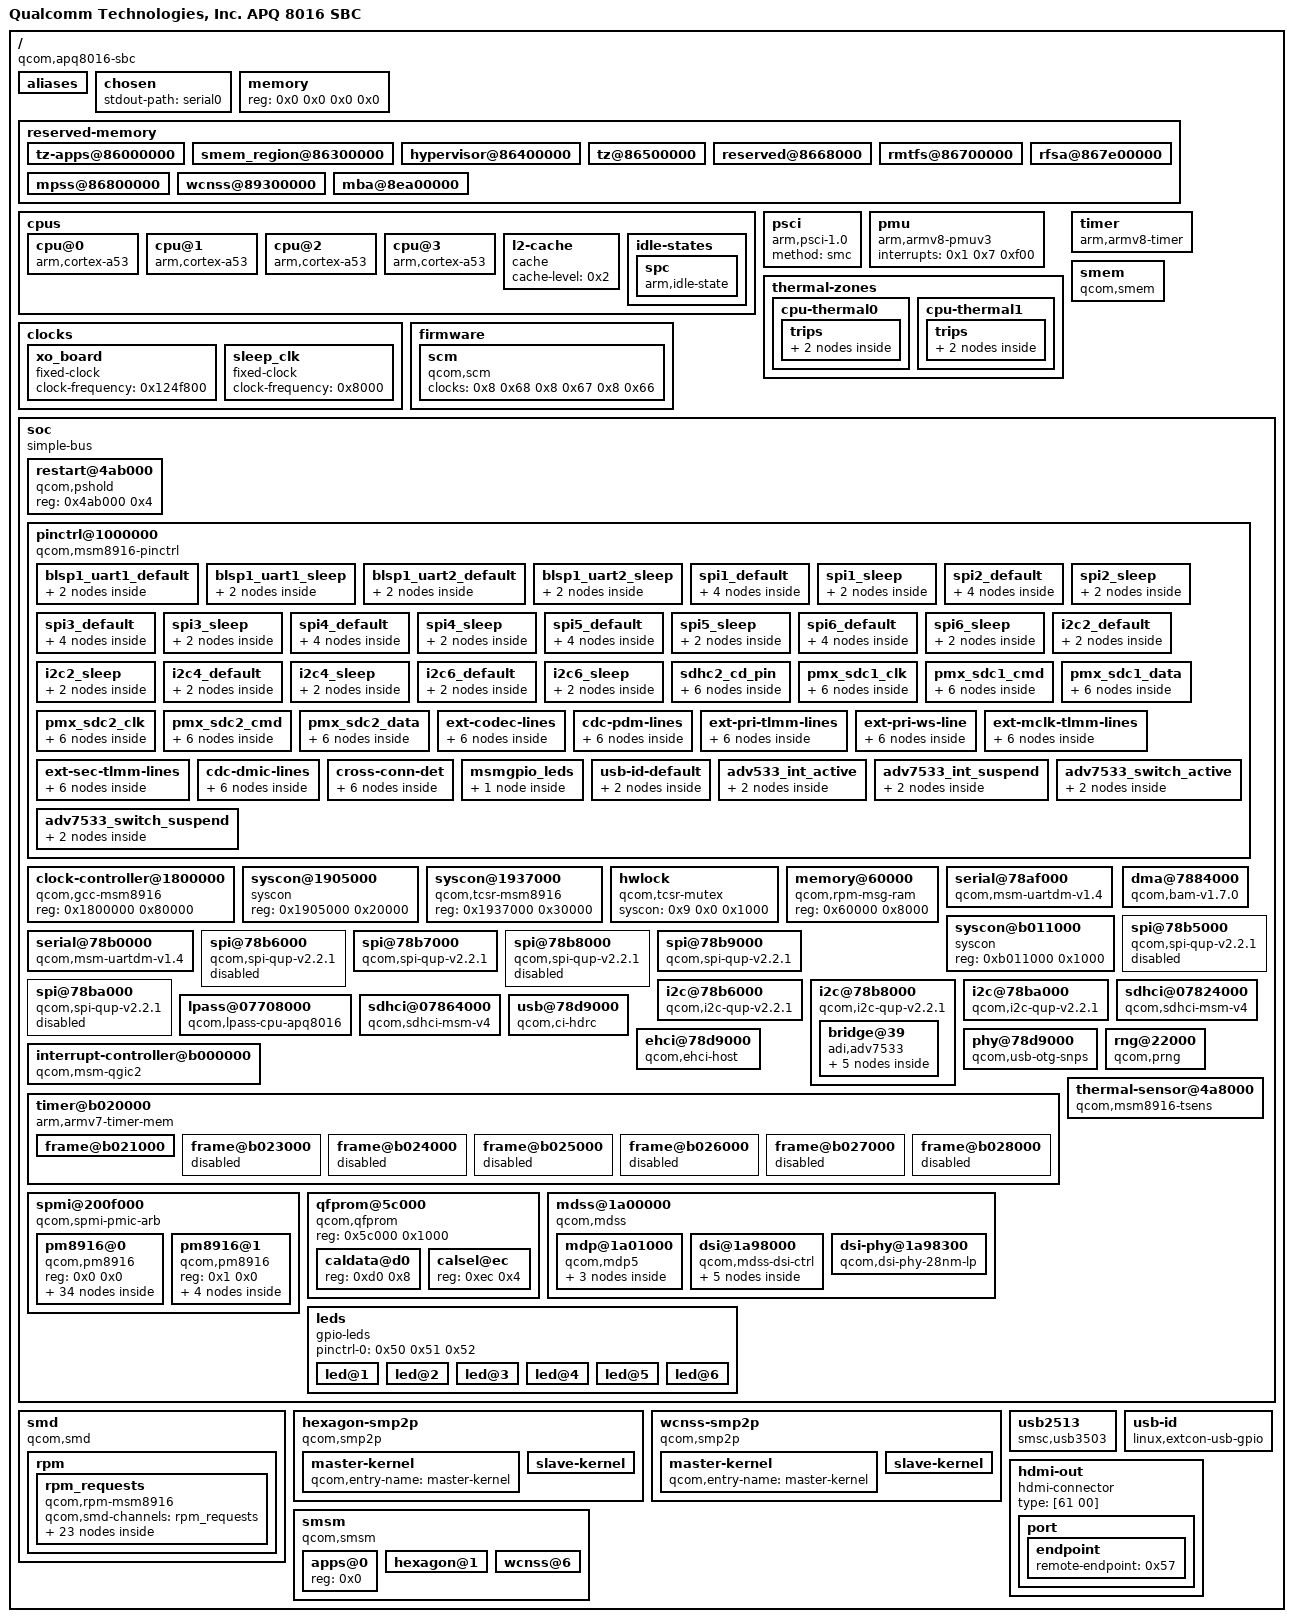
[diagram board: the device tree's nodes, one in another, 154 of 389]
/dts-v1/;

/ {
	model = "Qualcomm Technologies, Inc. APQ 8016 SBC";
	compatible = "qcom,apq8016-sbc", "qcom,apq8016", "qcom,sbc";
	interrupt-parent = <0x1>;
	#address-cells = <0x2>;
	#size-cells = <0x2>;

	aliases {
		sdhc1 = "/soc/sdhci@07824000";
		sdhc2 = "/soc/sdhci@07864000";
		serial0 = "/soc/serial@78b0000";
		serial1 = "/soc/serial@78af000";
		usid0 = "/soc/spmi@200f000/pm8916@0";
		i2c0 = "/soc/i2c@78b6000";
		i2c1 = "/soc/i2c@78ba000";
		i2c3 = "/soc/i2c@78b8000";
		spi0 = "/soc/spi@78b9000";
		spi1 = "/soc/spi@78b7000";
	};

	chosen {
		stdout-path = "serial0";
	};

	memory {
		device_type = "memory";
		reg = <0x0 0x0 0x0 0x0>;
	};

	reserved-memory {
		#address-cells = <0x2>;
		#size-cells = <0x2>;
		ranges;

		tz-apps@86000000 {
			reg = <0x0 0x86000000 0x0 0x300000>;
			no-map;
		};

		smem_region@86300000 {
			reg = <0x0 0x86300000 0x0 0x100000>;
			no-map;
			linux,phandle = <0x5>;
			phandle = <0x5>;
		};

		hypervisor@86400000 {
			reg = <0x0 0x86400000 0x0 0x100000>;
			no-map;
		};

		tz@86500000 {
			reg = <0x0 0x86500000 0x0 0x180000>;
			no-map;
		};

		reserved@8668000 {
			reg = <0x0 0x86680000 0x0 0x80000>;
			no-map;
		};

		rmtfs@86700000 {
			reg = <0x0 0x86700000 0x0 0xe0000>;
			no-map;
		};

		rfsa@867e00000 {
			reg = <0x0 0x867e0000 0x0 0x20000>;
			no-map;
		};

		mpss@86800000 {
			reg = <0x0 0x86800000 0x0 0x2b00000>;
			no-map;
		};

		wcnss@89300000 {
			reg = <0x0 0x89300000 0x0 0x600000>;
			no-map;
		};

		mba@8ea00000 {
			no-map;
			reg = <0x0 0x8ea00000 0x0 0x100000>;
		};
	};

	cpus {
		#address-cells = <0x1>;
		#size-cells = <0x0>;

		cpu@0 {
			device_type = "cpu";
			compatible = "arm,cortex-a53", "arm,armv8";
			reg = <0x0>;
			next-level-cache = <0x2>;
			enable-method = "psci";
			cpu-idle-states = <0x3>;
		};

		cpu@1 {
			device_type = "cpu";
			compatible = "arm,cortex-a53", "arm,armv8";
			reg = <0x1>;
			next-level-cache = <0x2>;
			enable-method = "psci";
			cpu-idle-states = <0x3>;
		};

		cpu@2 {
			device_type = "cpu";
			compatible = "arm,cortex-a53", "arm,armv8";
			reg = <0x2>;
			next-level-cache = <0x2>;
			enable-method = "psci";
			cpu-idle-states = <0x3>;
		};

		cpu@3 {
			device_type = "cpu";
			compatible = "arm,cortex-a53", "arm,armv8";
			reg = <0x3>;
			next-level-cache = <0x2>;
			enable-method = "psci";
			cpu-idle-states = <0x3>;
		};

		l2-cache {
			compatible = "cache";
			cache-level = <0x2>;
			linux,phandle = <0x2>;
			phandle = <0x2>;
		};

		idle-states {

			spc {
				compatible = "arm,idle-state";
				arm,psci-suspend-param = <0x40000002>;
				entry-latency-us = <0x82>;
				exit-latency-us = <0x96>;
				min-residency-us = <0x7d0>;
				local-timer-stop;
				linux,phandle = <0x3>;
				phandle = <0x3>;
			};
		};
	};

	psci {
		compatible = "arm,psci-1.0";
		method = "smc";
	};

	pmu {
		compatible = "arm,armv8-pmuv3";
		interrupts = <0x1 0x7 0xf00>;
	};

	thermal-zones {

		cpu-thermal0 {
			polling-delay-passive = <0xfa>;
			polling-delay = <0x3e8>;
			thermal-sensors = <0x4 0x4>;

			trips {

				trip0 {
					temperature = <0x124f8>;
					hysteresis = <0x7d0>;
					type = "passive";
				};

				trip1 {
					temperature = <0x1adb0>;
					hysteresis = <0x7d0>;
					type = "critical";
				};
			};
		};

		cpu-thermal1 {
			polling-delay-passive = <0xfa>;
			polling-delay = <0x3e8>;
			thermal-sensors = <0x4 0x3>;

			trips {

				trip0 {
					temperature = <0x124f8>;
					hysteresis = <0x7d0>;
					type = "passive";
				};

				trip1 {
					temperature = <0x1adb0>;
					hysteresis = <0x7d0>;
					type = "critical";
				};
			};
		};
	};

	timer {
		compatible = "arm,armv8-timer";
		interrupts = <0x1 0x2 0xf08 0x1 0x3 0xf08 0x1 0x4 0xf08 0x1 0x1 0xf08>;
	};

	clocks {

		xo_board {
			compatible = "fixed-clock";
			#clock-cells = <0x0>;
			clock-frequency = <0x124f800>;
		};

		sleep_clk {
			compatible = "fixed-clock";
			#clock-cells = <0x0>;
			clock-frequency = <0x8000>;
		};
	};

	smem {
		compatible = "qcom,smem";
		memory-region = <0x5>;
		qcom,rpm-msg-ram = <0x6>;
		hwlocks = <0x7 0x3>;
	};

	firmware {

		scm {
			compatible = "qcom,scm";
			clocks = <0x8 0x68 0x8 0x67 0x8 0x66>;
			clock-names = "core", "bus", "iface";
			#reset-cells = <0x1>;
		};
	};

	soc {
		#address-cells = <0x1>;
		#size-cells = <0x1>;
		ranges = <0x0 0x0 0x0 0xffffffff>;
		compatible = "simple-bus";

		restart@4ab000 {
			compatible = "qcom,pshold";
			reg = <0x4ab000 0x4>;
		};

		pinctrl@1000000 {
			compatible = "qcom,msm8916-pinctrl";
			reg = <0x1000000 0x300000>;
			interrupts = <0x0 0xd0 0x4>;
			gpio-controller;
			#gpio-cells = <0x2>;
			interrupt-controller;
			#interrupt-cells = <0x2>;
			linux,phandle = <0x1f>;
			phandle = <0x1f>;

			blsp1_uart1_default {
				linux,phandle = <0xb>;
				phandle = <0xb>;

				pinmux {
					function = "blsp_uart1";
					pins = "gpio0", "gpio1", "gpio2", "gpio3";
				};

				pinconf {
					pins = "gpio0", "gpio1", "gpio2", "gpio3";
					drive-strength = <0x10>;
					bias-disable;
				};
			};

			blsp1_uart1_sleep {
				linux,phandle = <0xc>;
				phandle = <0xc>;

				pinmux {
					function = "gpio";
					pins = "gpio0", "gpio1", "gpio2", "gpio3";
				};

				pinconf {
					pins = "gpio0", "gpio1", "gpio2", "gpio3";
					drive-strength = <0x2>;
					bias-pull-down;
				};
			};

			blsp1_uart2_default {
				linux,phandle = <0xd>;
				phandle = <0xd>;

				pinmux {
					function = "blsp_uart2";
					pins = "gpio4", "gpio5";
				};

				pinconf {
					pins = "gpio4", "gpio5";
					drive-strength = <0x10>;
					bias-disable;
				};
			};

			blsp1_uart2_sleep {
				linux,phandle = <0xe>;
				phandle = <0xe>;

				pinmux {
					function = "gpio";
					pins = "gpio4", "gpio5";
				};

				pinconf {
					pins = "gpio4", "gpio5";
					drive-strength = <0x2>;
					bias-pull-down;
				};
			};

			spi1_default {
				linux,phandle = <0xf>;
				phandle = <0xf>;

				pinmux {
					function = "blsp_spi1";
					pins = "gpio0", "gpio1", "gpio3";
				};

				pinmux_cs {
					function = "gpio";
					pins = "gpio2";
				};

				pinconf {
					pins = "gpio0", "gpio1", "gpio3";
					drive-strength = <0xc>;
					bias-disable;
				};

				pinconf_cs {
					pins = "gpio2";
					drive-strength = <0x10>;
					bias-disable;
					output-high;
				};
			};

			spi1_sleep {
				linux,phandle = <0x10>;
				phandle = <0x10>;

				pinmux {
					function = "gpio";
					pins = "gpio0", "gpio1", "gpio2", "gpio3";
				};

				pinconf {
					pins = "gpio0", "gpio1", "gpio2", "gpio3";
					drive-strength = <0x2>;
					bias-pull-down;
				};
			};

			spi2_default {
				linux,phandle = <0x11>;
				phandle = <0x11>;

				pinmux {
					function = "blsp_spi2";
					pins = "gpio4", "gpio5", "gpio7";
				};

				pinmux_cs {
					function = "gpio";
					pins = "gpio6";
				};

				pinconf {
					pins = "gpio4", "gpio5", "gpio7";
					drive-strength = <0xc>;
					bias-disable;
				};

				pinconf_cs {
					pins = "gpio6";
					drive-strength = <0x10>;
					bias-disable;
					output-high;
				};
			};

			spi2_sleep {
				linux,phandle = <0x12>;
				phandle = <0x12>;

				pinmux {
					function = "gpio";
					pins = "gpio4", "gpio5", "gpio6", "gpio7";
				};

				pinconf {
					pins = "gpio4", "gpio5", "gpio6", "gpio7";
					drive-strength = <0x2>;
					bias-pull-down;
				};
			};

			spi3_default {
				linux,phandle = <0x13>;
				phandle = <0x13>;

				pinmux {
					function = "blsp_spi3";
					pins = "gpio8", "gpio9", "gpio11";
				};

				pinmux_cs {
					function = "gpio";
					pins = "gpio10";
				};

				pinconf {
					pins = "gpio8", "gpio9", "gpio11";
					drive-strength = <0xc>;
					bias-disable;
				};

				pinconf_cs {
					pins = "gpio10";
					drive-strength = <0x10>;
					bias-disable;
					output-high;
				};
			};

			spi3_sleep {
				linux,phandle = <0x14>;
				phandle = <0x14>;

				pinmux {
					function = "gpio";
					pins = "gpio8", "gpio9", "gpio10", "gpio11";
				};

				pinconf {
					pins = "gpio8", "gpio9", "gpio10", "gpio11";
					drive-strength = <0x2>;
					bias-pull-down;
				};
			};

			spi4_default {
				linux,phandle = <0x15>;
				phandle = <0x15>;

				pinmux {
					function = "blsp_spi4";
					pins = "gpio12", "gpio13", "gpio15";
				};

				pinmux_cs {
					function = "gpio";
					pins = "gpio14";
				};

				pinconf {
					pins = "gpio12", "gpio13", "gpio15";
					drive-strength = <0xc>;
					bias-disable;
				};

				pinconf_cs {
					pins = "gpio14";
					drive-strength = <0x10>;
					bias-disable;
					output-high;
				};
			};

			spi4_sleep {
				linux,phandle = <0x16>;
				phandle = <0x16>;

				pinmux {
					function = "gpio";
					pins = "gpio12", "gpio13", "gpio14", "gpio15";
				};

				pinconf {
					pins = "gpio12", "gpio13", "gpio14", "gpio15";
					drive-strength = <0x2>;
					bias-pull-down;
				};
			};

			spi5_default {
				linux,phandle = <0x17>;
				phandle = <0x17>;

				pinmux {
					function = "blsp_spi5";
					pins = "gpio16", "gpio17", "gpio19";
				};

				pinmux_cs {
					function = "gpio";
					pins = "gpio18";
				};

				pinconf {
					pins = "gpio16", "gpio17", "gpio19";
					drive-strength = <0xc>;
					bias-disable;
				};

				pinconf_cs {
					pins = "gpio18";
					drive-strength = <0x10>;
					bias-disable;
					output-high;
				};
			};

			spi5_sleep {
				linux,phandle = <0x18>;
				phandle = <0x18>;

				pinmux {
					function = "gpio";
					pins = "gpio16", "gpio17", "gpio18", "gpio19";
				};

				pinconf {
					pins = "gpio16", "gpio17", "gpio18", "gpio19";
					drive-strength = <0x2>;
					bias-pull-down;
				};
			};

			spi6_default {
				linux,phandle = <0x19>;
				phandle = <0x19>;

				pinmux {
					function = "blsp_spi6";
					pins = "gpio20", "gpio21", "gpio23";
				};

				pinmux_cs {
					function = "gpio";
					pins = "gpio22";
				};

				pinconf {
					pins = "gpio20", "gpio21", "gpio23";
					drive-strength = <0xc>;
					bias-disable;
				};

				pinconf_cs {
					pins = "gpio22";
					drive-strength = <0x10>;
					bias-disable;
					output-high;
				};
			};

			spi6_sleep {
				linux,phandle = <0x1a>;
				phandle = <0x1a>;

				pinmux {
					function = "gpio";
					pins = "gpio20", "gpio21", "gpio22", "gpio23";
				};

				pinconf {
					pins = "gpio20", "gpio21", "gpio22", "gpio23";
					drive-strength = <0x2>;
					bias-pull-down;
				};
			};

			i2c2_default {
				linux,phandle = <0x1b>;
				phandle = <0x1b>;

				pinmux {
					function = "blsp_i2c2";
					pins = "gpio6", "gpio7";
				};

				pinconf {
					pins = "gpio6", "gpio7";
					drive-strength = <0x10>;
					bias-disable = <0x0>;
				};
			};

			i2c2_sleep {
				linux,phandle = <0x1c>;
				phandle = <0x1c>;

				pinmux {
					function = "gpio";
					pins = "gpio6", "gpio7";
				};

				pinconf {
					pins = "gpio6", "gpio7";
					drive-strength = <0x2>;
					bias-disable = <0x0>;
				};
			};

			i2c4_default {
				linux,phandle = <0x1d>;
				phandle = <0x1d>;

				pinmux {
					function = "blsp_i2c4";
					pins = "gpio14", "gpio15";
				};

				pinconf {
					pins = "gpio14", "gpio15";
					drive-strength = <0x10>;
					bias-disable = <0x0>;
				};
			};

			i2c4_sleep {
				linux,phandle = <0x1e>;
				phandle = <0x1e>;

				pinmux {
					function = "gpio";
					pins = "gpio14", "gpio15";
				};

				pinconf {
					pins = "gpio14", "gpio15";
					drive-strength = <0x2>;
					bias-disable = <0x0>;
				};
			};

			i2c6_default {
				linux,phandle = <0x28>;
				phandle = <0x28>;

				pinmux {
					function = "blsp_i2c6";
					pins = "gpio22", "gpio23";
				};

				pinconf {
					pins = "gpio22", "gpio23";
					drive-strength = <0x10>;
					bias-disable = <0x0>;
				};
			};

			i2c6_sleep {
				linux,phandle = <0x29>;
				phandle = <0x29>;

				pinmux {
					function = "gpio";
					pins = "gpio22", "gpio23";
				};

				pinconf {
					pins = "gpio22", "gpio23";
					drive-strength = <0x2>;
					bias-disable = <0x0>;
				};
			};

			sdhc2_cd_pin {

				cd_on {
					linux,phandle = <0x37>;
					phandle = <0x37>;

					pinmux {
						function = "gpio";
						pins = "gpio38";
					};

					pinconf {
						pins = "gpio38";
						drive-strength = <0x2>;
						bias-pull-up;
					};
				};

				cd_off {
					linux,phandle = <0x3b>;
					phandle = <0x3b>;

					pinmux {
						function = "gpio";
						pins = "gpio38";
					};

					pinconf {
						pins = "gpio38";
						drive-strength = <0x2>;
						bias-disable;
					};
				};
			};

			pmx_sdc1_clk {

				clk_on {
					linux,phandle = <0x2c>;
					phandle = <0x2c>;

					pinmux {
						pins = "sdc1_clk";
					};

					pinconf {
						pins = "sdc1_clk";
						bias-disable;
						drive-strength = <0x10>;
					};
				};

				clk_off {
					linux,phandle = <0x2f>;
					phandle = <0x2f>;

					pinmux {
						pins = "sdc1_clk";
					};

					pinconf {
						pins = "sdc1_clk";
						bias-disable;
						drive-strength = <0x2>;
					};
				};
			};

			pmx_sdc1_cmd {

				cmd_on {
					linux,phandle = <0x2d>;
					phandle = <0x2d>;

					pinmux {
						pins = "sdc1_cmd";
					};

					pinconf {
						pins = "sdc1_cmd";
						bias-pull-up;
						drive-strength = <0xa>;
					};
				};

				cmd_off {
					linux,phandle = <0x30>;
					phandle = <0x30>;

					pinmux {
						pins = "sdc1_cmd";
					};

					pinconf {
						pins = "sdc1_cmd";
						bias-pull-up;
						drive-strength = <0x2>;
					};
				};
			};

			pmx_sdc1_data {

				data_on {
					linux,phandle = <0x2e>;
					phandle = <0x2e>;

					pinmux {
						pins = "sdc1_data";
					};

					pinconf {
						pins = "sdc1_data";
						bias-pull-up;
						drive-strength = <0xa>;
					};
				};

				data_off {
					linux,phandle = <0x31>;
					phandle = <0x31>;

					pinmux {
						pins = "sdc1_data";
					};

					pinconf {
						pins = "sdc1_data";
						bias-pull-up;
						drive-strength = <0x2>;
					};
				};
			};

			pmx_sdc2_clk {

				clk_on {
					linux,phandle = <0x34>;
					phandle = <0x34>;

					pinmux {
						pins = "sdc2_clk";
					};

					pinconf {
						pins = "sdc2_clk";
						bias-disable;
						drive-strength = <0x10>;
					};
				};

				clk_off {
					linux,phandle = <0x38>;
					phandle = <0x38>;

					pinmux {
						pins = "sdc2_clk";
					};

					pinconf {
						pins = "sdc2_clk";
						bias-disable;
						drive-strength = <0x2>;
					};
				};
			};

			pmx_sdc2_cmd {

				cmd_on {
					linux,phandle = <0x35>;
					phandle = <0x35>;

					pinmux {
						pins = "sdc2_cmd";
					};

					pinconf {
						pins = "sdc2_cmd";
						bias-pull-up;
						drive-strength = <0xa>;
					};
				};

				cmd_off {
					linux,phandle = <0x39>;
					phandle = <0x39>;

					pinmux {
						pins = "sdc2_cmd";
					};

					pinconf {
						pins = "sdc2_cmd";
						bias-pull-up;
						drive-strength = <0x2>;
					};
				};
			};

			pmx_sdc2_data {

				data_on {
					linux,phandle = <0x36>;
					phandle = <0x36>;

					pinmux {
						pins = "sdc2_data";
					};

					pinconf {
						pins = "sdc2_data";
						bias-pull-up;
						drive-strength = <0xa>;
					};
				};

				data_off {
					linux,phandle = <0x3a>;
					phandle = <0x3a>;

					pinmux {
						pins = "sdc2_data";
					};

					pinconf {
						pins = "sdc2_data";
						bias-pull-up;
						drive-strength = <0x2>;
					};
				};
			};

			ext-codec-lines {

				lines_on {

					pinmux {
						function = "gpio";
						pins = "gpio67";
					};

					pinconf {
						pins = "gpio67";
						drive-strength = <0x8>;
						bias-disable;
						output-high;
					};
				};

				lines_off {

					pinmux {
						function = "gpio";
						pins = "gpio67";
					};

					pinconf {
						pins = "gpio67";
						drive-strength = <0x2>;
						bias-disable;
					};
				};
			};

			cdc-pdm-lines {

				pdm_lines_on {

					pinmux {
						function = "cdc_pdm0";
						pins = "gpio63", "gpio64", "gpio65", "gpio66", "gpio67", "gpio68";
					};

					pinconf {
						pins = "gpio63", "gpio64", "gpio65", "gpio66", "gpio67", "gpio68";
						drive-strength = <0x8>;
						bias-disable;
					};
				};

				pdm_lines_off {

					pinmux {
						function = "cdc_pdm0";
						pins = "gpio63", "gpio64", "gpio65", "gpio66", "gpio67", "gpio68";
					};

					pinconf {
						pins = "gpio63", "gpio64", "gpio65", "gpio66", "gpio67", "gpio68";
						drive-strength = <0x2>;
						bias-pull-down;
					};
				};
			};

			ext-pri-tlmm-lines {

				ext_pa_on {

					pinmux {
						function = "pri_mi2s";
						pins = "gpio113", "gpio114", "gpio115", "gpio116";
					};

					pinconf {
						pins = "gpio113", "gpio114", "gpio115", "gpio116";
						drive-strength = <0x8>;
						bias-disable;
					};
				};

				ext_pa_off {

					pinmux {
						function = "pri_mi2s";
						pins = "gpio113", "gpio114", "gpio115", "gpio116";
					};

					pinconf {
						pins = "gpio113", "gpio114", "gpio115", "gpio116";
						drive-strength = <0x2>;
						bias-disable;
					};
				};
			};

			ext-pri-ws-line {

				ext_pa_on {

					pinmux {
						function = "pri_mi2s_ws";
						pins = "gpio110";
					};

					pinconf {
						pins = "gpio110";
						drive-strength = <0x8>;
						bias-disable;
					};
				};

				ext_pa_off {

					pinmux {
						function = "pri_mi2s_ws";
						pins = "gpio110";
					};

					pinconf {
						pins = "gpio110";
						drive-strength = <0x2>;
						bias-disable;
					};
				};
			};

			ext-mclk-tlmm-lines {

				mclk_lines_on {

					pinmux {
						function = "pri_mi2s";
						pins = "gpio116";
					};

					pinconf {
						pins = "gpio116";
						drive-strength = <0x8>;
						bias-disable;
					};
				};

				mclk_lines_off {

					pinmux {
						function = "pri_mi2s";
						pins = "gpio116";
					};

					pinconf {
						pins = "gpio116";
						drive-strength = <0x2>;
						bias-disable;
					};
				};
			};

			ext-sec-tlmm-lines {

				tlmm_lines_on {

					pinmux {
						function = "sec_mi2s";
						pins = "gpio112", "gpio117", "gpio118", "gpio119";
					};

					pinconf {
						pins = "gpio112", "gpio117", "gpio118", "gpio119";
						drive-strength = <0x8>;
						bias-disable;
					};
				};

				tlmm_lines_off {

					pinmux {
						function = "sec_mi2s";
						pins = "gpio112", "gpio117", "gpio118", "gpio119";
					};

					pinconf {
						pins = "gpio112", "gpio117", "gpio118", "gpio119";
						drive-strength = <0x2>;
						bias-disable;
					};
				};
			};

			cdc-dmic-lines {

				dmic_lines_on {

					pinmux_dmic0_clk {
						function = "dmic0_clk";
						pins = "gpio0";
					};

					pinmux_dmic0_data {
						function = "dmic0_data";
						pins = "gpio1";
					};

					pinconf {
						pins = "gpio0", "gpio1";
						drive-strength = <0x8>;
					};
				};

				dmic_lines_off {

					pinconf {
						pins = "gpio0", "gpio1";
						drive-strength = <0x2>;
						bias-disable;
					};
				};
			};

			cross-conn-det {

				lines_on {

					pinmux {
						function = "gpio";
						pins = "gpio120";
					};

					pinconf {
						pins = "gpio120";
						drive-strength = <0x8>;
						output-low;
						bias-pull-down;
					};
				};

				lines_off {

					pinmux {
						function = "gpio";
						pins = "gpio120";
					};

					pinconf {
						pins = "gpio120";
						drive-strength = <0x2>;
						bias-disable;
					};
				};
			};

			msmgpio_leds {
				linux,phandle = <0x50>;
				phandle = <0x50>;

				pinconf {
					pins = "gpio21", "gpio120";
					function = "gpio";
					output-low;
				};
			};

			usb-id-default {
				linux,phandle = <0x56>;
				phandle = <0x56>;

				pinmux {
					function = "gpio";
					pins = "gpio121";
				};

				pinconf {
					pins = "gpio121";
					drive-strength = <0x8>;
					input-enable;
					bias-pull-up;
				};
			};

			adv533_int_active {
				linux,phandle = <0x22>;
				phandle = <0x22>;

				pinmux {
					function = "gpio";
					pins = "gpio31";
				};

				pinconf {
					pins = "gpio31";
					drive-strength = <0x10>;
					bias-disable;
				};
			};

			adv7533_int_suspend {
				linux,phandle = <0x24>;
				phandle = <0x24>;

				pinmux {
					function = "gpio";
					pins = "gpio31";
				};

				pinconf {
					pins = "gpio31";
					drive-strength = <0x2>;
					bias-disable;
				};
			};

			adv7533_switch_active {
				linux,phandle = <0x23>;
				phandle = <0x23>;

				pinmux {
					function = "gpio";
					pins = "gpio32";
				};

				pinconf {
					pins = "gpio32";
					drive-strength = <0x10>;
					bias-disable;
				};
			};

			adv7533_switch_suspend {
				linux,phandle = <0x25>;
				phandle = <0x25>;

				pinmux {
					function = "gpio";
					pins = "gpio32";
				};

				pinconf {
					pins = "gpio32";
					drive-strength = <0x2>;
					bias-disable;
				};
			};
		};

		clock-controller@1800000 {
			compatible = "qcom,gcc-msm8916";
			#clock-cells = <0x1>;
			#reset-cells = <0x1>;
			#power-domain-cells = <0x1>;
			reg = <0x1800000 0x80000>;
			linux,phandle = <0x8>;
			phandle = <0x8>;
		};

		syscon@1905000 {
			compatible = "syscon";
			reg = <0x1905000 0x20000>;
			linux,phandle = <0x9>;
			phandle = <0x9>;
		};

		syscon@1937000 {
			compatible = "qcom,tcsr-msm8916", "syscon";
			reg = <0x1937000 0x30000>;
		};

		hwlock {
			compatible = "qcom,tcsr-mutex";
			syscon = <0x9 0x0 0x1000>;
			#hwlock-cells = <0x1>;
			linux,phandle = <0x7>;
			phandle = <0x7>;
		};

		memory@60000 {
			compatible = "qcom,rpm-msg-ram";
			reg = <0x60000 0x8000>;
			linux,phandle = <0x6>;
			phandle = <0x6>;
		};

		serial@78af000 {
			compatible = "qcom,msm-uartdm-v1.4", "qcom,msm-uartdm";
			reg = <0x78af000 0x200>;
			interrupts = <0x0 0x6b 0x4>;
			clocks = <0x8 0x44 0x8 0x36>;
			clock-names = "core", "iface";
			dmas = <0xa 0x1 0xa 0x0>;
			dma-names = "rx", "tx";
			status = "okay";
			label = "LS-UART0";
			pinctrl-names = "default", "sleep";
			pinctrl-0 = <0xb>;
			pinctrl-1 = <0xc>;
		};

		syscon@b011000 {
			compatible = "syscon";
			reg = <0xb011000 0x1000>;
			linux,phandle = <0x54>;
			phandle = <0x54>;
		};

		serial@78b0000 {
			compatible = "qcom,msm-uartdm-v1.4", "qcom,msm-uartdm";
			reg = <0x78b0000 0x200>;
			interrupts = <0x0 0x6c 0x4>;
			clocks = <0x8 0x45 0x8 0x36>;
			clock-names = "core", "iface";
			dmas = <0xa 0x3 0xa 0x2>;
			dma-names = "rx", "tx";
			status = "okay";
			label = "LS-UART1";
			pinctrl-names = "default", "sleep";
			pinctrl-0 = <0xd>;
			pinctrl-1 = <0xe>;
		};

		dma@7884000 {
			compatible = "qcom,bam-v1.7.0";
			reg = <0x7884000 0x23000>;
			interrupts = <0x0 0xee 0x4>;
			clocks = <0x8 0x36>;
			clock-names = "bam_clk";
			#dma-cells = <0x1>;
			qcom,ee = <0x0>;
			status = "okay";
			linux,phandle = <0xa>;
			phandle = <0xa>;
		};

		spi@78b5000 {
			compatible = "qcom,spi-qup-v2.2.1";
			reg = <0x78b5000 0x600>;
			interrupts = <0x0 0x5f 0x4>;
			clocks = <0x8 0x39 0x8 0x36>;
			clock-names = "core", "iface";
			dmas = <0xa 0x5 0xa 0x4>;
			dma-names = "rx", "tx";
			pinctrl-names = "default", "sleep";
			pinctrl-0 = <0xf>;
			pinctrl-1 = <0x10>;
			#address-cells = <0x1>;
			#size-cells = <0x0>;
			status = "disabled";
		};

		spi@78b6000 {
			compatible = "qcom,spi-qup-v2.2.1";
			reg = <0x78b6000 0x600>;
			interrupts = <0x0 0x60 0x4>;
			clocks = <0x8 0x3b 0x8 0x36>;
			clock-names = "core", "iface";
			dmas = <0xa 0x7 0xa 0x6>;
			dma-names = "rx", "tx";
			pinctrl-names = "default", "sleep";
			pinctrl-0 = <0x11>;
			pinctrl-1 = <0x12>;
			#address-cells = <0x1>;
			#size-cells = <0x0>;
			status = "disabled";
		};

		spi@78b7000 {
			compatible = "qcom,spi-qup-v2.2.1";
			reg = <0x78b7000 0x600>;
			interrupts = <0x0 0x61 0x4>;
			clocks = <0x8 0x3d 0x8 0x36>;
			clock-names = "core", "iface";
			dmas = <0xa 0x9 0xa 0x8>;
			dma-names = "rx", "tx";
			pinctrl-names = "default", "sleep";
			pinctrl-0 = <0x13>;
			pinctrl-1 = <0x14>;
			#address-cells = <0x1>;
			#size-cells = <0x0>;
			status = "okay";
			label = "HS-SPI1";
		};

		spi@78b8000 {
			compatible = "qcom,spi-qup-v2.2.1";
			reg = <0x78b8000 0x600>;
			interrupts = <0x0 0x62 0x4>;
			clocks = <0x8 0x3f 0x8 0x36>;
			clock-names = "core", "iface";
			dmas = <0xa 0xb 0xa 0xa>;
			dma-names = "rx", "tx";
			pinctrl-names = "default", "sleep";
			pinctrl-0 = <0x15>;
			pinctrl-1 = <0x16>;
			#address-cells = <0x1>;
			#size-cells = <0x0>;
			status = "disabled";
		};

		spi@78b9000 {
			compatible = "qcom,spi-qup-v2.2.1";
			reg = <0x78b9000 0x600>;
			interrupts = <0x0 0x63 0x4>;
			clocks = <0x8 0x41 0x8 0x36>;
			clock-names = "core", "iface";
			dmas = <0xa 0xd 0xa 0xc>;
			dma-names = "rx", "tx";
			pinctrl-names = "default", "sleep";
			pinctrl-0 = <0x17>;
			pinctrl-1 = <0x18>;
			#address-cells = <0x1>;
			#size-cells = <0x0>;
			status = "okay";
			label = "LS-SPI0";
		};

		spi@78ba000 {
			compatible = "qcom,spi-qup-v2.2.1";
			reg = <0x78ba000 0x600>;
			interrupts = <0x0 0x64 0x4>;
			clocks = <0x8 0x43 0x8 0x36>;
			clock-names = "core", "iface";
			dmas = <0xa 0xf 0xa 0xe>;
			dma-names = "rx", "tx";
			pinctrl-names = "default", "sleep";
			pinctrl-0 = <0x19>;
			pinctrl-1 = <0x1a>;
			#address-cells = <0x1>;
			#size-cells = <0x0>;
			status = "disabled";
		};

		i2c@78b6000 {
			compatible = "qcom,i2c-qup-v2.2.1";
			reg = <0x78b6000 0x1000>;
			interrupts = <0x0 0x60 0x0>;
			clocks = <0x8 0x36 0x8 0x3a>;
			clock-names = "iface", "core";
			pinctrl-names = "default", "sleep";
			pinctrl-0 = <0x1b>;
			pinctrl-1 = <0x1c>;
			#address-cells = <0x1>;
			#size-cells = <0x0>;
			status = "okay";
			label = "LS-I2C0";
		};

		i2c@78b8000 {
			compatible = "qcom,i2c-qup-v2.2.1";
			reg = <0x78b8000 0x1000>;
			interrupts = <0x0 0x62 0x0>;
			clocks = <0x8 0x36 0x8 0x3e>;
			clock-names = "iface", "core";
			pinctrl-names = "default", "sleep";
			pinctrl-0 = <0x1d>;
			pinctrl-1 = <0x1e>;
			#address-cells = <0x1>;
			#size-cells = <0x0>;
			status = "okay";
			label = "HS-I2C2";

			bridge@39 {
				status = "okay";
				compatible = "adi,adv7533";
				reg = <0x39>;
				interrupt-parent = <0x1f>;
				interrupts = <0x1f 0x2>;
				adi,dsi-lanes = <0x4>;
				pd-gpios = <0x1f 0x20 0x0>;
				avdd-supply = <0x20>;
				v1p2-supply = <0x20>;
				v3p3-supply = <0x21>;
				pinctrl-names = "default", "sleep";
				pinctrl-0 = <0x22 0x23>;
				pinctrl-1 = <0x24 0x25>;

				ports {
					#address-cells = <0x1>;
					#size-cells = <0x0>;

					port@0 {
						reg = <0x0>;

						endpoint {
							remote-endpoint = <0x26>;
							linux,phandle = <0x4f>;
							phandle = <0x4f>;
						};
					};

					port@1 {
						reg = <0x1>;

						endpoint {
							remote-endpoint = <0x27>;
							linux,phandle = <0x57>;
							phandle = <0x57>;
						};
					};
				};
			};
		};

		i2c@78ba000 {
			compatible = "qcom,i2c-qup-v2.2.1";
			reg = <0x78ba000 0x1000>;
			interrupts = <0x0 0x64 0x0>;
			clocks = <0x8 0x36 0x8 0x42>;
			clock-names = "iface", "core";
			pinctrl-names = "default", "sleep";
			pinctrl-0 = <0x28>;
			pinctrl-1 = <0x29>;
			#address-cells = <0x1>;
			#size-cells = <0x0>;
			status = "okay";
			label = "LS-I2C1";
		};

		lpass@07708000 {
			status = "okay";
			compatible = "qcom,lpass-cpu-apq8016";
			clocks = <0x8 0x9a 0x8 0x96 0x8 0x97 0x8 0x9c 0x8 0x9d 0x8 0x9d 0x8 0x9e>;
			clock-names = "ahbix-clk", "pcnoc-mport-clk", "pcnoc-sway-clk", "mi2s-bit-clk0", "mi2s-bit-clk1", "mi2s-bit-clk2", "mi2s-bit-clk3";
			#sound-dai-cells = <0x1>;
			interrupts = <0x0 0xa0 0x0>;
			interrupt-names = "lpass-irq-lpaif";
			reg = <0x7708000 0x10000>;
			reg-names = "lpass-lpaif";
		};

		sdhci@07824000 {
			compatible = "qcom,sdhci-msm-v4";
			reg = <0x7824900 0x11c 0x7824000 0x800>;
			reg-names = "hc_mem", "core_mem";
			interrupts = <0x0 0x7b 0x0 0x0 0x8a 0x0>;
			interrupt-names = "hc_irq", "pwr_irq";
			clocks = <0x8 0x7b 0x8 0x7a>;
			clock-names = "core", "iface";
			bus-width = <0x8>;
			non-removable;
			status = "okay";
			vmmc-supply = <0x2a>;
			vqmmc-supply = <0x2b>;
			pinctrl-names = "default", "sleep";
			pinctrl-0 = <0x2c 0x2d 0x2e>;
			pinctrl-1 = <0x2f 0x30 0x31>;
		};

		sdhci@07864000 {
			compatible = "qcom,sdhci-msm-v4";
			reg = <0x7864900 0x11c 0x7864000 0x800>;
			reg-names = "hc_mem", "core_mem";
			interrupts = <0x0 0x7d 0x0 0x0 0xdd 0x0>;
			interrupt-names = "hc_irq", "pwr_irq";
			clocks = <0x8 0x7d 0x8 0x7c>;
			clock-names = "core", "iface";
			bus-width = <0x4>;
			status = "okay";
			vmmc-supply = <0x32>;
			vqmmc-supply = <0x33>;
			pinctrl-names = "default", "sleep";
			pinctrl-0 = <0x34 0x35 0x36 0x37>;
			pinctrl-1 = <0x38 0x39 0x3a 0x3b>;
			cd-gpios = <0x1f 0x26 0x1>;
		};

		usb@78d9000 {
			compatible = "qcom,ci-hdrc";
			reg = <0x78d9000 0x400>;
			dr_mode = "peripheral";
			interrupts = <0x0 0x86 0x4>;
			usb-phy = <0x3c>;
			status = "okay";
			extcon = <0x3d 0x3d>;
		};

		ehci@78d9000 {
			compatible = "qcom,ehci-host";
			reg = <0x78d9000 0x400>;
			interrupts = <0x0 0x86 0x4>;
			usb-phy = <0x3c>;
			status = "okay";
		};

		phy@78d9000 {
			compatible = "qcom,usb-otg-snps";
			reg = <0x78d9000 0x400>;
			interrupts = <0x0 0x86 0x4 0x0 0x8c 0x4>;
			qcom,vdd-levels = <0x7a120 0xf4240 0x142440>;
			qcom,phy-init-sequence = <0x44 0x6b 0x24 0x13>;
			dr_mode = "otg";
			qcom,otg-control = <0x2>;
			qcom,manual-pullup;
			clocks = <0x8 0x85 0x8 0x86 0x8 0x84>;
			clock-names = "iface", "core", "sleep";
			resets = <0x8 0x23 0x8 0x22>;
			reset-names = "phy", "link";
			status = "okay";
			v1p8-supply = <0x3e>;
			v3p3-supply = <0x3f>;
			vddcx-supply = <0x40>;
			extcon = <0x3d 0x3d>;
			switch-gpio = <0x41 0x4 0x0>;
			pinctrl-names = "default";
			pinctrl-0 = <0x42>;
			linux,phandle = <0x3c>;
			phandle = <0x3c>;
		};

		interrupt-controller@b000000 {
			compatible = "qcom,msm-qgic2";
			interrupt-controller;
			#interrupt-cells = <0x3>;
			reg = <0xb000000 0x1000 0xb002000 0x1000>;
			linux,phandle = <0x1>;
			phandle = <0x1>;
		};

		timer@b020000 {
			#address-cells = <0x1>;
			#size-cells = <0x1>;
			ranges;
			compatible = "arm,armv7-timer-mem";
			reg = <0xb020000 0x1000>;
			clock-frequency = <0x124f800>;

			frame@b021000 {
				frame-number = <0x0>;
				interrupts = <0x0 0x8 0x4 0x0 0x7 0x4>;
				reg = <0xb021000 0x1000 0xb022000 0x1000>;
			};

			frame@b023000 {
				frame-number = <0x1>;
				interrupts = <0x0 0x9 0x4>;
				reg = <0xb023000 0x1000>;
				status = "disabled";
			};

			frame@b024000 {
				frame-number = <0x2>;
				interrupts = <0x0 0xa 0x4>;
				reg = <0xb024000 0x1000>;
				status = "disabled";
			};

			frame@b025000 {
				frame-number = <0x3>;
				interrupts = <0x0 0xb 0x4>;
				reg = <0xb025000 0x1000>;
				status = "disabled";
			};

			frame@b026000 {
				frame-number = <0x4>;
				interrupts = <0x0 0xc 0x4>;
				reg = <0xb026000 0x1000>;
				status = "disabled";
			};

			frame@b027000 {
				frame-number = <0x5>;
				interrupts = <0x0 0xd 0x4>;
				reg = <0xb027000 0x1000>;
				status = "disabled";
			};

			frame@b028000 {
				frame-number = <0x6>;
				interrupts = <0x0 0xe 0x4>;
				reg = <0xb028000 0x1000>;
				status = "disabled";
			};
		};

		spmi@200f000 {
			compatible = "qcom,spmi-pmic-arb";
			reg = <0x200f000 0x1000 0x2400000 0x400000 0x2c00000 0x400000 0x3800000 0x200000 0x200a000 0x2100>;
			reg-names = "core", "chnls", "obsrvr", "intr", "cnfg";
			interrupt-names = "periph_irq";
			interrupts = <0x0 0xbe 0x4>;
			qcom,ee = <0x0>;
			qcom,channel = <0x0>;
			#address-cells = <0x2>;
			#size-cells = <0x0>;
			interrupt-controller;
			#interrupt-cells = <0x4>;
			linux,phandle = <0x46>;
			phandle = <0x46>;

			pm8916@0 {
				compatible = "qcom,pm8916", "qcom,spmi-pmic";
				reg = <0x0 0x0>;
				#address-cells = <0x1>;
				#size-cells = <0x1>;

				qcom,revid@100 {
					compatible = "qcom,qpnp-revid";
					reg = <0x100 0x100>;
					linux,phandle = <0x43>;
					phandle = <0x43>;
				};

				qcom,power-on@800 {
					compatible = "qcom,qpnp-power-on";
					reg = <0x800 0x100>;
					interrupts = <0x0 0x8 0x0 0x0 0x0 0x8 0x1 0x0>;
					interrupt-names = "kpdpwr", "resin";
					qcom,pon-dbc-delay = <0x3d09>;
					qcom,system-reset;
					qcom,clear-warm-reset;
					qcom,store-hard-reset-reason;

					qcom,pon_1 {
						qcom,pon-type = <0x0>;
						qcom,support-reset = <0x1>;
						qcom,pull-up = <0x1>;
						qcom,s1-timer = <0x2810>;
						qcom,s2-timer = <0x7d0>;
						qcom,s2-type = <0x1>;
						linux,code = <0x74>;
					};

					qcom,pon_2 {
						qcom,pon-type = <0x1>;
						qcom,pull-up = <0x1>;
						linux,code = <0x72>;
					};
				};

				pinctrl@c000 {
					compatible = "qcom,pm8916-gpio";
					reg = <0xc000 0x400>;
					gpio-controller;
					#gpio-cells = <0x2>;
					interrupts = <0x0 0xc0 0x0 0x0 0x0 0xc1 0x0 0x0 0x0 0xc2 0x0 0x0 0x0 0xc3 0x0 0x0>;
					interrupt-names = "pm8916_gpio1", "pm8916_gpio2", "pm8916_gpio3", "pm8916_gpio4";
					linux,phandle = <0x41>;
					phandle = <0x41>;

					usb_hub_reset_pm {

						pinconf {
							pins = "gpio3";
							function = "normal";
							output-low;
						};
					};

					usb_sw_sel_pm {
						linux,phandle = <0x42>;
						phandle = <0x42>;

						pinconf {
							pins = "gpio4";
							function = "normal";
							power-source = <0x0>;
							input-disable;
						};
					};

					pm8916_gpios_leds {
						linux,phandle = <0x51>;
						phandle = <0x51>;

						pinconf {
							pins = "gpio1", "gpio2";
							function = "normal";
							output-low;
						};
					};
				};

				mpps@a000 {
					compatible = "qcom,pm8916-mpp";
					reg = <0xa000 0x400>;
					gpio-controller;
					#gpio-cells = <0x2>;
					interrupts = <0x0 0xa0 0x0 0x0 0x0 0xa1 0x0 0x0 0x0 0xa2 0x0 0x0 0x0 0xa3 0x0 0x0>;
					interrupt-names = "pm8916_mpp1", "pm8916_mpp2", "pm8916_mpp3", "pm8916_mpp4";
					linux,phandle = <0x53>;
					phandle = <0x53>;

					pm8916_mpps_leds {
						linux,phandle = <0x52>;
						phandle = <0x52>;

						pinconf {
							pins = "mpp2", "mpp3";
							function = "digital";
							output-low;
						};
					};
				};

				qcom,coincell@2800 {
					compatible = "qcom,qpnp-coincell";
					reg = <0x2800 0x100>;
				};

				qcom,pm8916_rtc {
					compatible = "qcom,qpnp-rtc";
					#address-cells = <0x1>;
					#size-cells = <0x1>;
					qcom,qpnp-rtc-write = <0x0>;
					qcom,qpnp-rtc-alarm-pwrup = <0x0>;

					qcom,pm8916_rtc_rw@6000 {
						reg = <0x6000 0x100>;
					};

					qcom,pm8916_rtc_alarm@6100 {
						reg = <0x6100 0x100>;
						interrupts = <0x0 0x61 0x1 0x0>;
					};
				};

				vadc@3100 {
					compatible = "qcom,qpnp-vadc";
					reg = <0x3100 0x100>;
					#address-cells = <0x1>;
					#size-cells = <0x0>;
					interrupts = <0x0 0x31 0x0 0x1>;
					interrupt-names = "eoc-int-en-set";
					qcom,adc-bit-resolution = <0xf>;
					qcom,adc-vdd-reference = <0x708>;
					qcom,vadc-poll-eoc;
					qcom,pmic-revid = <0x43>;
					#thermal-sensor-cells = <0x1>;
					linux,phandle = <0x44>;
					phandle = <0x44>;

					chan@8 {
						label = "die_temp";
						reg = <0x8>;
						qcom,decimation = <0x0>;
						qcom,pre-div-channel-scaling = <0x0>;
						qcom,calibration-type = "absolute";
						qcom,scale-function = <0x3>;
						qcom,hw-settle-time = <0x0>;
						qcom,fast-avg-setup = <0x0>;
					};

					chan@9 {
						label = "ref_625mv";
						reg = <0x9>;
						qcom,decimation = <0x0>;
						qcom,pre-div-channel-scaling = <0x0>;
						qcom,calibration-type = "absolute";
						qcom,scale-function = <0x0>;
						qcom,hw-settle-time = <0x0>;
						qcom,fast-avg-setup = <0x0>;
					};

					chan@a {
						label = "ref_1250v";
						reg = <0xa>;
						qcom,decimation = <0x0>;
						qcom,pre-div-channel-scaling = <0x0>;
						qcom,calibration-type = "absolute";
						qcom,scale-function = <0x0>;
						qcom,hw-settle-time = <0x0>;
						qcom,fast-avg-setup = <0x0>;
					};
				};

				qcom,temp-alarm@2400 {
					compatible = "qcom,qpnp-temp-alarm";
					reg = <0x2400 0x100>;
					interrupts = <0x0 0x24 0x0 0x1>;
					label = "pm8916_tz";
					qcom,channel-num = <0x8>;
					qcom,threshold-set = <0x0>;
					qcom,temp_alarm-vadc = <0x44>;
					#thermal-sensor-cells = <0x0>;
				};

				vadc@3400 {
					compatible = "qcom,qpnp-adc-tm";
					reg = <0x3400 0x100>;
					#address-cells = <0x1>;
					#size-cells = <0x0>;
					interrupts = <0x0 0x34 0x0 0x1 0x0 0x34 0x3 0x1 0x0 0x34 0x4 0x1>;
					interrupt-names = "eoc-int-en-set", "high-thr-en-set", "low-thr-en-set";
					qcom,adc-bit-resolution = <0xf>;
					qcom,adc-vdd-reference = <0x708>;
					qcom,adc_tm-vadc = <0x44>;
					qcom,pmic-revid = <0x43>;
					linux,phandle = <0x45>;
					phandle = <0x45>;
				};

				qcom,charger {
					compatible = "qcom,qpnp-linear-charger";
					#address-cells = <0x1>;
					#size-cells = <0x1>;
					#cooling-cells = <0x2>;
					qcom,vddmax-mv = <0x1068>;
					qcom,vddsafe-mv = <0x1068>;
					qcom,vinmin-mv = <0x10d4>;
					qcom,ibatsafe-ma = <0x5a0>;
					qcom,thermal-mitigation = <0x5a0 0x2d0 0x276 0x0>;
					qcom,cool-bat-decidegc = <0x64>;
					qcom,warm-bat-decidegc = <0x1c2>;
					qcom,cool-bat-mv = <0x1004>;
					qcom,warm-bat-mv = <0x1004>;
					qcom,ibatmax-warm-ma = <0x168>;
					qcom,ibatmax-cool-ma = <0x168>;
					qcom,batt-hot-percentage = <0x19>;
					qcom,batt-cold-percentage = <0x50>;
					qcom,tchg-mins = <0xe8>;
					qcom,resume-soc = <0x63>;
					qcom,chg-vadc = <0x44>;
					qcom,chg-adc_tm = <0x45>;
					status = "disabled";

					qcom,chgr@1000 {
						reg = <0x1000 0x100>;
						interrupts = <0x0 0x10 0x7 0x1 0x0 0x10 0x6 0x1 0x0 0x10 0x5 0x3 0x0 0x10 0x0 0x2>;
						interrupt-names = "chg-done", "chg-failed", "fast-chg-on", "vbat-det-lo";
					};

					qcom,bat-if@1200 {
						reg = <0x1200 0x100>;
						interrupts = <0x0 0x12 0x1 0x3 0x0 0x12 0x0 0x3>;
						interrupt-names = "bat-temp-ok", "batt-pres";
					};

					qcom,usb-chgpth@1300 {
						reg = <0x1300 0x100>;
						interrupts = <0x0 0x13 0x4 0x3 0x0 0x13 0x2 0x1 0x0 0x13 0x1 0x3>;
						interrupt-names = "usb-over-temp", "chg-gone", "usbin-valid";
					};

					qcom,chg-misc@1600 {
						reg = <0x1600 0x100>;
					};
				};

				qcom,vmbms {
					compatible = "qcom,qpnp-vm-bms";
					#address-cells = <0x1>;
					#size-cells = <0x1>;
					status = "disabled";
					qcom,v-cutoff-uv = <0x33e140>;
					qcom,max-voltage-uv = <0x401640>;
					qcom,r-conn-mohm = <0x0>;
					qcom,shutdown-soc-valid-limit = <0x64>;
					qcom,low-soc-calculate-soc-threshold = <0xf>;
					qcom,low-voltage-calculate-soc-ms = <0x3e8>;
					qcom,low-soc-calculate-soc-ms = <0x1388>;
					qcom,calculate-soc-ms = <0x4e20>;
					qcom,volatge-soc-timeout-ms = <0xea60>;
					qcom,low-voltage-threshold = <0x34a490>;
					qcom,s3-ocv-tolerence-uv = <0x4b0>;
					qcom,s2-fifo-length = <0x5>;
					qcom,low-soc-fifo-length = <0x2>;
					qcom,bms-vadc = <0x44>;
					qcom,bms-adc_tm = <0x45>;
					qcom,pmic-revid = <0x43>;
					qcom,force-s3-on-suspend;
					qcom,force-s2-in-charging;
					qcom,report-charger-eoc;

					qcom,batt-pres-status@1208 {
						reg = <0x1208 0x1>;
					};

					qcom,qpnp-chg-pres@1008 {
						reg = <0x1008 0x1>;
					};

					qcom,vm-bms@4000 {
						reg = <0x4000 0x100>;
						interrupts = <0x0 0x40 0x0 0x0 0x0 0x40 0x1 0x0 0x0 0x40 0x2 0x0 0x0 0x40 0x3 0x0 0x0 0x40 0x4 0x0 0x0 0x40 0x5 0x0>;
						interrupt-names = "leave_cv", "enter_cv", "good_ocv", "ocv_thr", "fifo_update_done", "fsm_state_change";
					};
				};

				qcom,leds@a100 {
					compatible = "qcom,leds-qpnp";
					reg = <0xa100 0x100>;
					label = "mpp";
				};
			};

			pm8916@1 {
				compatible = "qcom,pm8916", "qcom,spmi-pmic";
				reg = <0x1 0x0>;
				#address-cells = <0x1>;
				#size-cells = <0x1>;

				qcom,pwms@bc00 {
					compatible = "qcom,pwm-lpg";
					reg = <0xbc00 0x100>;
					reg-names = "lpg-base";
					#pwm-cells = <0x2>;
				};

				qcom,vibrator@c000 {
					compatible = "qcom,qpnp-vibrator";
					reg = <0xc000 0x100>;
					label = "vibrator";
					status = "disabled";
				};

				msm8x16_wcd_codec@f000 {
					compatible = "qcom,msm8x16_wcd_codec";
					reg = <0xf000 0x100>;
					interrupt-parent = <0x46>;
					interrupts = <0x1 0xf0 0x0 0x0 0x1 0xf0 0x1 0x0 0x1 0xf0 0x2 0x0 0x1 0xf0 0x3 0x0 0x1 0xf0 0x4 0x0 0x1 0xf0 0x5 0x0 0x1 0xf0 0x6 0x0 0x1 0xf0 0x7 0x0>;
					interrupt-names = "spk_cnp_int", "spk_clip_int", "spk_ocp_int", "ins_rem_det1", "but_rel_det", "but_press_det", "ins_rem_det", "mbhc_int";
					cdc-vdda-cp-supply = <0x47>;
					qcom,cdc-vdda-cp-voltage = <0x1b7740 0x2191c0>;
					qcom,cdc-vdda-cp-current = <0xbbfd0>;
					cdc-vdda-h-supply = <0x2b>;
					qcom,cdc-vdda-h-voltage = <0x1b7740 0x1b7740>;
					qcom,cdc-vdda-h-current = <0x4e20>;
					cdc-vdd-px-supply = <0x47>;
					qcom,cdc-vdd-px-voltage = <0x1b7740 0x2191c0>;
					qcom,cdc-vdd-px-current = <0xbbfd0>;
					cdc-vdd-pa-supply = <0x2b>;
					qcom,cdc-vdd-pa-voltage = <0x1b7740 0x1b7740>;
					qcom,cdc-vdd-pa-current = <0x1388>;
					cdc-vdd-mic-bias-supply = <0x3f>;
					qcom,cdc-vdd-mic-bias-voltage = <0x2eebb8 0x2eebb8>;
					qcom,cdc-vdd-mic-bias-current = <0x61a8>;
					qcom,cdc-mclk-clk-rate = <0x927c00>;
					qcom,cdc-static-supplies = "cdc-vdda-h", "cdc-vdd-px", "cdc-vdd-pa", "cdc-vdda-cp";
					qcom,cdc-on-demand-supplies = "cdc-vdd-mic-bias";
					qcom,subsys-name = "modem";
				};

				msm8x16_wcd_codec@f100 {
					compatible = "qcom,msm8x16_wcd_codec";
					reg = <0xf100 0x100>;
					interrupt-parent = <0x46>;
					interrupts = <0x1 0xf1 0x0 0x0 0x1 0xf1 0x1 0x0 0x1 0xf1 0x2 0x0 0x1 0xf1 0x3 0x0 0x1 0xf1 0x4 0x0 0x1 0xf1 0x5 0x0>;
					interrupt-names = "ear_ocp_int", "hphr_ocp_int", "hphl_ocp_det", "ear_cnp_int", "hphr_cnp_int", "hphl_cnp_int";
				};
			};
		};

		rng@22000 {
			compatible = "qcom,prng";
			reg = <0x22000 0x200>;
			clocks = <0x8 0x79>;
			clock-names = "core";
		};

		qfprom@5c000 {
			compatible = "qcom,qfprom";
			reg = <0x5c000 0x1000>;
			#address-cells = <0x1>;
			#size-cells = <0x1>;

			caldata@d0 {
				reg = <0xd0 0x8>;
				linux,phandle = <0x48>;
				phandle = <0x48>;
			};

			calsel@ec {
				reg = <0xec 0x4>;
				linux,phandle = <0x49>;
				phandle = <0x49>;
			};
		};

		thermal-sensor@4a8000 {
			compatible = "qcom,msm8916-tsens";
			reg = <0x4a8000 0x2000>;
			nvmem-cells = <0x48 0x49>;
			nvmem-cell-names = "calib", "calib_sel";
			#thermal-sensor-cells = <0x1>;
			linux,phandle = <0x4>;
			phandle = <0x4>;
		};

		mdss@1a00000 {
			compatible = "qcom,mdss";
			reg = <0x1a00000 0x1000 0x1ac8000 0x3000>;
			reg-names = "mdss_phys", "vbif_phys";
			power-domains = <0x8 0x2>;
			clocks = <0x8 0x6d 0x8 0x6e 0x8 0x73>;
			clock-names = "iface_clk", "bus_clk", "vsync_clk";
			interrupts = <0x0 0x48 0x0>;
			interrupt-controller;
			#interrupt-cells = <0x1>;
			#address-cells = <0x1>;
			#size-cells = <0x1>;
			ranges;
			status = "okay";
			linux,phandle = <0x4a>;
			phandle = <0x4a>;

			mdp@1a01000 {
				compatible = "qcom,mdp5";
				reg = <0x1a01000 0x90000>;
				reg-names = "mdp_phys";
				interrupt-parent = <0x4a>;
				interrupts = <0x0>;
				clocks = <0x8 0x6d 0x8 0x6e 0x8 0x71 0x8 0x73>;
				clock-names = "iface_clk", "bus_clk", "core_clk", "vsync_clk";
				status = "okay";

				ports {
					#address-cells = <0x1>;
					#size-cells = <0x0>;

					port@0 {
						reg = <0x0>;

						endpoint {
							remote-endpoint = <0x4b>;
							linux,phandle = <0x4e>;
							phandle = <0x4e>;
						};
					};
				};
			};

			dsi@1a98000 {
				compatible = "qcom,mdss-dsi-ctrl";
				reg = <0x1a98000 0x25c>;
				reg-names = "dsi_ctrl";
				interrupt-parent = <0x4a>;
				interrupts = <0x4>;
				assigned-clocks = <0x8 0x2b 0x8 0x2e>;
				assigned-clock-parents = <0x4c 0x0 0x4c 0x1>;
				clocks = <0x8 0x71 0x8 0x6d 0x8 0x6e 0x8 0x6f 0x8 0x72 0x8 0x70>;
				clock-names = "mdp_core_clk", "iface_clk", "bus_clk", "byte_clk", "pixel_clk", "core_clk";
				phys = <0x4c>;
				phy-names = "dsi-phy";
				status = "okay";
				vdda-supply = <0x4d>;
				vddio-supply = <0x20>;

				ports {
					#address-cells = <0x1>;
					#size-cells = <0x0>;

					port@0 {
						reg = <0x0>;

						endpoint {
							remote-endpoint = <0x4e>;
							linux,phandle = <0x4b>;
							phandle = <0x4b>;
						};
					};

					port@1 {
						reg = <0x1>;

						endpoint {
							remote-endpoint = <0x4f>;
							data-lanes = <0x0 0x1 0x2 0x3>;
							linux,phandle = <0x26>;
							phandle = <0x26>;
						};
					};
				};
			};

			dsi-phy@1a98300 {
				compatible = "qcom,dsi-phy-28nm-lp";
				reg = <0x1a98300 0xd4 0x1a98500 0x280 0x1a98780 0x30>;
				reg-names = "dsi_pll", "dsi_phy", "dsi_phy_regulator";
				#clock-cells = <0x1>;
				#phy-cells = <0x0>;
				clocks = <0x8 0x6d>;
				clock-names = "iface_clk";
				status = "okay";
				vddio-supply = <0x20>;
				linux,phandle = <0x4c>;
				phandle = <0x4c>;
			};
		};

		leds {
			pinctrl-names = "default";
			pinctrl-0 = <0x50 0x51 0x52>;
			compatible = "gpio-leds";

			led@1 {
				label = "apq8016-sbc:green:user1";
				gpios = <0x1f 0x15 0x0>;
				linux,default-trigger = "heartbeat";
				default-state = "off";
			};

			led@2 {
				label = "apq8016-sbc:green:user2";
				gpios = <0x1f 0x78 0x0>;
				linux,default-trigger = "mmc0";
				default-state = "off";
			};

			led@3 {
				label = "apq8016-sbc:green:user3";
				gpios = <0x41 0x1 0x0>;
				linux,default-trigger = "mmc1";
				default-state = "off";
			};

			led@4 {
				label = "apq8016-sbc:green:user4";
				gpios = <0x41 0x2 0x0>;
				linux,default-trigger = "none";
				default-state = "off";
			};

			led@5 {
				label = "apq8016-sbc:yellow:wlan";
				gpios = <0x53 0x2 0x0>;
				linux,default-trigger = "wlan";
				default-state = "off";
			};

			led@6 {
				label = "apq8016-sbc:blue:bt";
				gpios = <0x53 0x3 0x0>;
				linux,default-trigger = "bluetooth-power";
				default-state = "off";
			};
		};
	};

	smd {
		compatible = "qcom,smd";

		rpm {
			interrupts = <0x0 0xa8 0x1>;
			qcom,ipc = <0x54 0x8 0x0>;
			qcom,smd-edge = <0xf>;

			rpm_requests {
				compatible = "qcom,rpm-msm8916";
				qcom,smd-channels = "rpm_requests";

				qcom,rpmcc {
					compatible = "qcom,rpmcc-msm8916", "qcom,rpmcc";
					#clock-cells = <0x1>;
				};

				pm8916-regulators {
					compatible = "qcom,rpm-pm8916-regulators";
					vdd_l1_l2_l3-supply = <0x55>;
					vdd_l5-supply = <0x55>;
					vdd_l4_l5_l6-supply = <0x47>;
					vdd_l7-supply = <0x47>;

					s1 {
						regulator-min-microvolt = <0x5b8d8>;
						regulator-max-microvolt = <0x17d590>;
						linux,phandle = <0x40>;
						phandle = <0x40>;
					};

					s3 {
						regulator-min-microvolt = <0x5b8d8>;
						regulator-max-microvolt = <0x17d590>;
						linux,phandle = <0x55>;
						phandle = <0x55>;
					};

					s4 {
						regulator-min-microvolt = <0x1b7740>;
						regulator-max-microvolt = <0x1b7740>;
						regulator-always-on;
						regulator-boot-on;
						linux,phandle = <0x47>;
						phandle = <0x47>;
					};

					l1 {
						regulator-min-microvolt = <0x5b8d8>;
						regulator-max-microvolt = <0x174508>;
					};

					l2 {
						regulator-min-microvolt = <0x5b8d8>;
						regulator-max-microvolt = <0x174508>;
						linux,phandle = <0x4d>;
						phandle = <0x4d>;
					};

					l3 {
						regulator-min-microvolt = <0x5b8d8>;
						regulator-max-microvolt = <0x174508>;
					};

					l4 {
						regulator-min-microvolt = <0x1ab3f0>;
						regulator-max-microvolt = <0x32eb28>;
					};

					l5 {
						regulator-min-microvolt = <0x1ab3f0>;
						regulator-max-microvolt = <0x32eb28>;
						linux,phandle = <0x2b>;
						phandle = <0x2b>;
					};

					l6 {
						regulator-min-microvolt = <0x1ab3f0>;
						regulator-max-microvolt = <0x32eb28>;
						linux,phandle = <0x20>;
						phandle = <0x20>;
					};

					l7 {
						regulator-min-microvolt = <0x1ab3f0>;
						regulator-max-microvolt = <0x32eb28>;
						linux,phandle = <0x3e>;
						phandle = <0x3e>;
					};

					l8 {
						regulator-min-microvolt = <0x1ab3f0>;
						regulator-max-microvolt = <0x32eb28>;
						linux,phandle = <0x2a>;
						phandle = <0x2a>;
					};

					l9 {
						regulator-min-microvolt = <0x1ab3f0>;
						regulator-max-microvolt = <0x32eb28>;
					};

					l10 {
						regulator-min-microvolt = <0x1ab3f0>;
						regulator-max-microvolt = <0x32eb28>;
					};

					l11 {
						regulator-min-microvolt = <0x1ab3f0>;
						regulator-max-microvolt = <0x32eb28>;
						regulator-allow-set-load;
						regulator-system-load = <0x30d40>;
						linux,phandle = <0x32>;
						phandle = <0x32>;
					};

					l12 {
						regulator-min-microvolt = <0x1ab3f0>;
						regulator-max-microvolt = <0x32eb28>;
						linux,phandle = <0x33>;
						phandle = <0x33>;
					};

					l13 {
						regulator-min-microvolt = <0x1ab3f0>;
						regulator-max-microvolt = <0x32eb28>;
						linux,phandle = <0x3f>;
						phandle = <0x3f>;
					};

					l14 {
						regulator-min-microvolt = <0x1ab3f0>;
						regulator-max-microvolt = <0x32eb28>;
					};

					l15 {
						regulator-min-microvolt = <0x1ab3f0>;
						regulator-max-microvolt = <0x32eb28>;
						regulator-always-on;
					};

					l16 {
						regulator-min-microvolt = <0x1ab3f0>;
						regulator-max-microvolt = <0x32eb28>;
					};

					l17 {
						regulator-min-microvolt = <0x1ab3f0>;
						regulator-max-microvolt = <0x32eb28>;
						linux,phandle = <0x21>;
						phandle = <0x21>;
					};

					l18 {
						regulator-min-microvolt = <0x1ab3f0>;
						regulator-max-microvolt = <0x32eb28>;
					};
				};
			};
		};
	};

	hexagon-smp2p {
		compatible = "qcom,smp2p";
		qcom,smem = <0x1b3 0x1ac>;
		interrupts = <0x0 0x1b 0x1>;
		qcom,ipc = <0x54 0x8 0xe>;
		qcom,local-pid = <0x0>;
		qcom,remote-pid = <0x1>;

		master-kernel {
			qcom,entry-name = "master-kernel";
			#qcom,smem-state-cells = <0x1>;
		};

		slave-kernel {
			qcom,entry-name = "slave-kernel";
			interrupt-controller;
			#interrupt-cells = <0x2>;
		};
	};

	wcnss-smp2p {
		compatible = "qcom,smp2p";
		qcom,smem = <0x1c3 0x1af>;
		interrupts = <0x0 0x8f 0x1>;
		qcom,ipc = <0x54 0x8 0x12>;
		qcom,local-pid = <0x0>;
		qcom,remote-pid = <0x4>;

		master-kernel {
			qcom,entry-name = "master-kernel";
			#qcom,smem-state-cells = <0x1>;
		};

		slave-kernel {
			qcom,entry-name = "slave-kernel";
			interrupt-controller;
			#interrupt-cells = <0x2>;
		};
	};

	smsm {
		compatible = "qcom,smsm";
		#address-cells = <0x1>;
		#size-cells = <0x0>;
		qcom,ipc-1 = <0x54 0x8 0xd>;
		qcom,ipc-3 = <0x54 0x8 0x13>;

		apps@0 {
			reg = <0x0>;
			#qcom,smem-state-cells = <0x1>;
		};

		hexagon@1 {
			reg = <0x1>;
			interrupts = <0x0 0x1a 0x1>;
			interrupt-controller;
			#interrupt-cells = <0x2>;
		};

		wcnss@6 {
			reg = <0x6>;
			interrupts = <0x0 0x90 0x1>;
			interrupt-controller;
			#interrupt-cells = <0x2>;
		};
	};

	usb2513 {
		compatible = "smsc,usb3503";
		reset-gpios = <0x41 0x3 0x1>;
		initial-mode = <0x1>;
	};

	usb-id {
		compatible = "linux,extcon-usb-gpio";
		id-gpio = <0x1f 0x79 0x0>;
		pinctrl-names = "default";
		pinctrl-0 = <0x56>;
		linux,phandle = <0x3d>;
		phandle = <0x3d>;
	};

	hdmi-out {
		compatible = "hdmi-connector";
		type = [61 00];

		port {

			endpoint {
				remote-endpoint = <0x57>;
				linux,phandle = <0x27>;
				phandle = <0x27>;
			};
		};
	};
};
